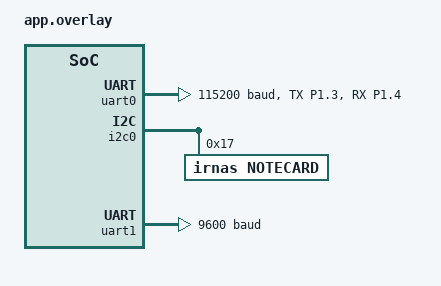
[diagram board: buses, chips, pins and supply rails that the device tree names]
&pinctrl {
	uart0_default: uart0_default {
		group1 {
			psels = <NRF_PSEL(UART_TX, 1, 3)>;
		};
		group2 {
			psels = <NRF_PSEL(UART_RX, 1, 4)>;
			bias-pull-up;
		};
	};

	uart0_sleep: uart0_sleep {
		group1 {
			psels = <NRF_PSEL(UART_TX, 1, 3)>,
				<NRF_PSEL(UART_RX, 1, 4)>;
			low-power-enable;
		};
	};
};

&uart0 {
	compatible = "nordic,nrf-uarte";
	current-speed = <115200>;
	pinctrl-0 = <&uart0_default>;
	pinctrl-1 = <&uart0_sleep>;
	pinctrl-names = "default", "sleep";

};

&i2c0 {
	notecard: notecard@17 {
		compatible = "irnas,notecard";
		reg = <0x17>;
	};
};
&uart1 {
	compatible = "nordic,nrf-uarte";
	current-speed = <9600>;
};

